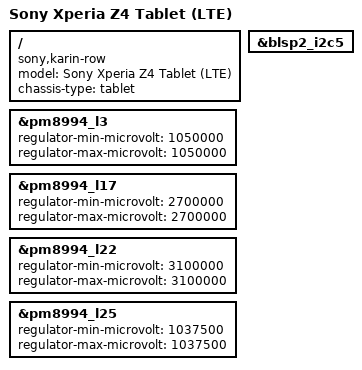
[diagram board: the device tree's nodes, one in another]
/dts-v1/;
#include "msm8994-sony-xperia-kitakami.dtsi"
/ {
	model = "Sony Xperia Z4 Tablet (LTE)";
	compatible = "sony,karin-row", "qcom,msm8994";
	chassis-type = "tablet";
};
&blsp2_i2c5 {
};
&pm8994_l3 {
	regulator-min-microvolt = <1050000>;
	regulator-max-microvolt = <1050000>;
};
&pm8994_l17 {
	regulator-min-microvolt = <2700000>;
	regulator-max-microvolt = <2700000>;
};
&pm8994_l22 {
	regulator-min-microvolt = <3100000>;
	regulator-max-microvolt = <3100000>;
};
&pm8994_l25 {
	regulator-min-microvolt = <1037500>;
	regulator-max-microvolt = <1037500>;
};
/delete-node/ &pm8994_l32;
/delete-node/ &touchscreen;
